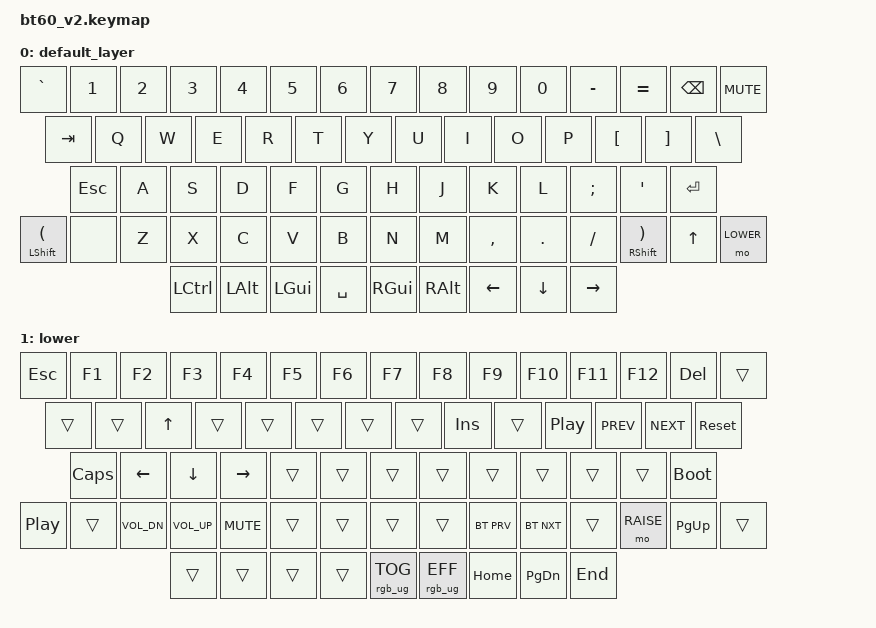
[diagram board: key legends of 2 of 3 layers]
#include <behaviors.dtsi>
#include <dt-bindings/zmk/keys.h>
#include <dt-bindings/zmk/bt.h>
#include <dt-bindings/zmk/rgb.h>
#include <dt-bindings/zmk/backlight.h>

#define DEFAULT 0
#define LOWER   1
#define RAISE   2

/ {
    combos {
        compatible = "zmk,combos";
        combo_l2 {
            timeout-ms = <50>;
            key-positions = <55 57>;
            bindings = <&mo RAISE>;
        };
    };
};

/ {
  chosen {
    zmk,matrix_transform = &all_1u_transform;
  };
  
  keymap {
    compatible = "zmk,keymap";
    default_layer {
        // --------------------------------------------------------------------------------------------
        // |GRAVE|  1  |  2  |  3  |  4  |  5  |  6  |  7  |  8  |  9  |  0  |  -  |  =  |BKSP |K_MUTE|
        // | TAB   |  Q  |  W  |  E  |  R  |  T  |  Y  |  U  |  I  |  O  |  P  |  [  |  ]  |    \     |
        // | ESC    |  A  |  S  |  D  |  F  |  G  |  H  |  J  |  K  |  L  |  ;  |  '  |     ENTER     |
        // | SHFT    |NONE|  Z  |  X  |  C  |  V  |  B  |  N  |  M  |  ,  |  .  | /   | SHFT | UP | 1 |
        // |  CTL  |  ALT  |  CMD  |           SPACE              | RCMD | RALT | LEFT | DOWN | RIGHT |
        // --------------------------------------------------------------------------------------------
      bindings = <
        &kp GRAVE  &kp N1  &kp N2  &kp N3  &kp N4  &kp N5  &kp N6  &kp N7  &kp N8  &kp N9  &kp N0  &kp MINUS  &kp EQUAL  &kp BSPC  &kp K_MUTE
        &kp TAB  &kp Q  &kp W  &kp E  &kp R  &kp T  &kp Y  &kp U  &kp I  &kp O  &kp P  &kp LBKT  &kp RBKT  &kp BSLH
        &kp ESC  &kp A  &kp S  &kp D  &kp F  &kp G  &kp H  &kp J  &kp K  &kp L  &kp SEMI  &kp SQT  &kp RET
        &mt LSHIFT LEFT_PARENTHESIS  &none  &kp Z  &kp X  &kp C  &kp V  &kp B  &kp N  &kp M  &kp COMMA  &kp DOT  &kp FSLH  &mt RIGHT_SHIFT RIGHT_PARENTHESIS  &kp UP  &mo LOWER
        &kp LCTRL  &kp LALT  &kp LGUI  &kp SPACE  &kp RGUI  &kp RALT  &kp LEFT  &kp DOWN  &kp RIGHT
      >;
      sensor-bindings = <&inc_dec_kp C_VOL_UP C_VOL_DN>;
    };
    lower {
        // ------------------------------------------------------------------------------------------
        // | ESC | F1  | F2  | F3  | F4  | F5  | F6  | F7  | F8  | F9  | F10 | F11 | F12 |BKSP | DEL |
        // | TAB  |  Q  |  UP  |  E  |  R  |  T  |  Y  |  U  | INS |  O  | PPAUSE| PREV| NEXT | RESET|
        // | CAPS  | LEFT| DOWN| RIGHT|  F  | G  |  H  |  J  |  K  |  L  |  :  |  '  |      BOOT     |
        // | PPAUSE|VOLDN|VOLUP|MUTE| C  | V  |  B  |  N  |  M  |BT_PREV|BT_NXT| / |  2  |PG_UP|  1  |
        // |  CTL  |  ALT |  CMD  |           SPACE              | RGBTOG | RALT | HOME | PG_DN | END  |
        // ------------------------------------------------------------------------------------------
      bindings = <
        &kp ESC  &kp F1  &kp F2  &kp F3  &kp F4  &kp F5  &kp F6  &kp F7  &kp F8  &kp F9  &kp F10  &kp F11  &kp F12  &kp DEL  &trans
        &trans  &trans  &kp UP  &trans  &trans  &trans  &trans  &trans  &kp INS  &trans  &kp C_PLAY_PAUSE  &kp C_PREV  &kp C_NEXT &sys_reset  
        &kp CLCK  &kp LEFT  &kp DOWN  &kp RIGHT  &trans  &trans  &trans  &trans  &trans  &trans  &trans  &trans  &bootloader
        &kp C_PLAY_PAUSE &trans  &kp C_VOL_DN  &kp C_VOL_UP  &kp C_MUTE  &trans  &trans  &trans  &trans  &bt BT_PRV  &bt BT_NXT  &trans  &mo RAISE  &kp PG_UP  &trans
        &trans  &trans &trans  &trans  &rgb_ug RGB_TOG  &rgb_ug RGB_EFF  &kp HOME  &kp PG_DN  &kp END
      >;
      sensor-bindings = <&inc_dec_kp PG_UP PG_DN>;
    };
    raise {
        // ------------------------------------------------------------------------------------------
        // | ESC| BT1| BT2| BT3| BT4| BT5| F6 | F7 | F8 | F9  | F10 | BT_PREV | BT_NXT |BT_CLR | DEL |
        // | TAB  |  Q  |  UP  |  E  |  R  |  T  |  Y  |  U  | INS |  O  | PPAUSE| PREV| NEXT | RESET|
        // | CAPS  | LEFT| DOWN| RIGHT|  F  | G  |  H  |  J  |  K  |  L  |  :  |  '  |      BOOT     |
        // | PPAUSE|VOLDN|VOLUP|MUTE| C  | V  |  B  |  N  |  M  |BT_PREV|BT_NXT| / |  2  |PG_UP|  1  |
        // | RGBTOG |  ALT |  CMD  |           SPACE              | RCMD | RALT | HOME | PG_DN | END  |
        // ------------------------------------------------------------------------------------------
      bindings = <
        &rgb_ug RGB_TOG  &bt BT_SEL 1  &bt BT_SEL 2  &bt BT_SEL 3  &bt BT_SEL 4  &bt BT_SEL 5  &trans  &trans  &trans  &trans  &trans  &bt BT_PRV  &bt BT_NXT  &bt BT_CLR  &trans
        &trans  &kp Z  &trans  &trans  &trans  &trans  &trans  &trans  &trans  &trans  &trans  &trans  &trans  &trans
        &trans  &trans  &trans  &trans  &trans  &trans  &trans  &trans  &trans  &trans  &trans  &trans  &trans
        &trans  &trans  &trans  &trans  &trans  &trans  &trans  &trans  &trans  &trans  &trans  &trans  &trans  &trans
        &rgb_ug RGB_TOG  &trans  &trans  &trans  &trans  &trans  &trans  &trans  &trans
      >;
      sensor-bindings = <&inc_dec_kp PG_UP PG_DN>;
    };
  };
};
